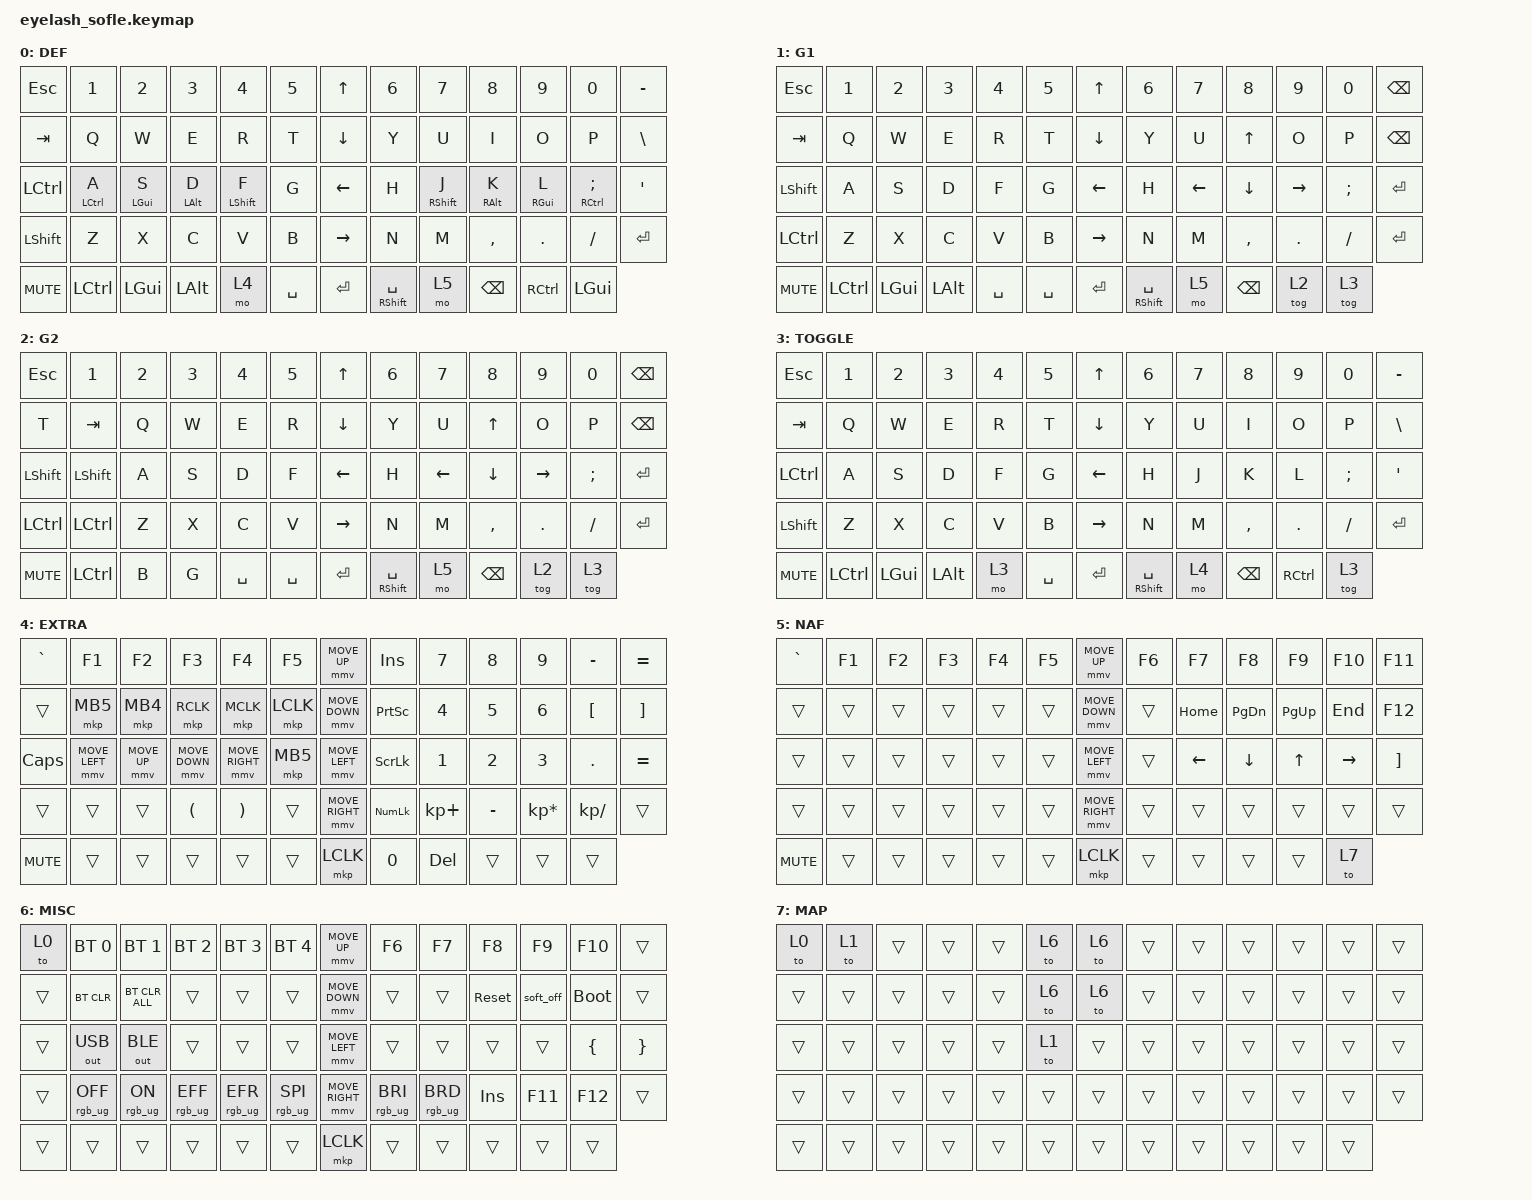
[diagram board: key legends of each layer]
#define ZMK_POINTING_DEFAULT_MOVE_VAL 1200  // 600
#define ZMK_POINTING_DEFAULT_SCRL_VAL 1   // 10

#include <input/processors.dtsi>
#include <zephyr/dt-bindings/input/input-event-codes.h>
#include <behaviors.dtsi>
#include <dt-bindings/zmk/bt.h>
#include <dt-bindings/zmk/ext_power.h>
#include <dt-bindings/zmk/keys.h>
#include <dt-bindings/zmk/pointing.h>
#include <dt-bindings/zmk/rgb.h>
#include <dt-bindings/zmk/outputs.h>

&mmv_input_listener { input-processors = <&zip_xy_scaler 2 1>; };

// &msc_input_listener { input-processors = <&zip_scroll_scaler 2 1>; };

&msc {
    acceleration-exponent = <0>;      // 0
    time-to-max-speed-ms = <300>;       // 300
    delay-ms = <0>;                   // 0
    trigger-period-ms = <2>;
};

&mmv {
    acceleration-exponent = <1>;
    time-to-max-speed-ms = <500>;
    trigger-period-ms = <16>;
};


/ {
    behaviors {
        hml: home_row_mod_left {
            compatible = "zmk,behavior-hold-tap";
            #binding-cells = <2>;
            flavor = "balanced";
            require-prior-idle-ms = <150>;
            tapping-term-ms = <280>;
            quick-tap-ms = <175>;
            bindings = <&kp>, <&kp>;

            hold-trigger-key-positions = < 8 9 10 11 12 13 21 22 23 24 25 26 34 35 36 37 38 39 46 47 48 49 50 51>; // List of keys on the right side of the keyboard
            hold-trigger-on-release;
        };

        hmr: home_row_mod_right {
            compatible = "zmk,behavior-hold-tap";
            #binding-cells = <2>;
            flavor = "balanced";
            require-prior-idle-ms = <150>;
            tapping-term-ms = <280>;
            quick-tap-ms = <175>;
            bindings = <&kp>, <&kp>;

            hold-trigger-key-positions = < 1 2 3 4 5 6 14 15 16 17 18 19 27 28 29 30 31 32 40 41 42 43 44 45>; // List of keys on the left side of the keyboard
            hold-trigger-on-release;
        };
    };
};

/ {

    scroll_encoder_vtcl: scroll_encoder_vtcl {
        compatible = "zmk,behavior-sensor-rotate";
        #sensor-binding-cells = <0>;
        bindings = <&msc MOVE_UP>, <&msc MOVE_DOWN>;
        tap-ms = <100>;
    };

    scroll_encoder_hzntl: scroll_encoder_hzntl {
        compatible = "zmk,behavior-sensor-rotate";
        #sensor-binding-cells = <0>;
        bindings = <&msc MOVE_LEFT>, <&msc MOVE_RIGHT>;
        tap-ms = <100>;
    };

    scroll_encoder_rgb: scroll_encoder_rgb {
        compatible = "zmk,behavior-sensor-rotate";
        #sensor-binding-cells = <0>;
        bindings = <&rgb_ug RGB_BRD>, <&rgb_ug RGB_BRI>;
        tap-ms = <100>;
    };

    keymap {
        compatible = "zmk,keymap";

        def_0 {
            bindings = <
&kp ESC     &kp N1          &kp N2         &kp N3          &kp N4          &kp N5          &kp UP_ARROW     &kp N6          &kp N7          &kp N8         &kp N9         &kp N0          &kp MINUS
&kp TAB     &kp Q           &kp W          &kp E           &kp R           &kp T           &kp DOWN_ARROW   &kp Y           &kp U           &kp I          &kp O          &kp P           &kp BSLH
&kp LCTRL   &hml LCTRL A    &hml LGUI S    &hml LALT D     &hml LSHIFT F   &kp G           &kp LEFT_ARROW   &kp H           &hmr RSHIFT J   &hmr RALT K    &hmr RGUI L    &hmr RCTRL SEMI &kp SQT
&kp LSHFT   &kp Z           &kp X          &kp C           &kp V           &kp B           &kp RIGHT_ARROW  &kp N           &kp M           &kp COMMA      &kp DOT        &kp FSLH        &kp ENTER
&kp C_MUTE  &kp LCTRL       &kp LGUI       &kp LALT        &mo 4           &kp SPACE       &kp ENTER        &mt RSHFT SPACE &mo 5           &kp BSPC       &kp RCTRL      &kp LGUI
            >;

            sensor-bindings = <&scroll_encoder_vtcl>;
            display-name = "DEF";
        };

        gaymink_1 {
            bindings = <
&kp ESC     &kp N1          &kp N2         &kp N3          &kp N4          &kp N5          &kp UP_ARROW     &kp N6          &kp N7          &kp N8         &kp N9         &kp N0          &kp BSPC
&kp TAB     &kp Q           &kp W          &kp E           &kp R           &kp T           &kp DOWN_ARROW   &kp Y           &kp U           &kp UP         &kp O          &kp P           &kp BSPC
&kp LSHFT   &kp A           &kp S          &kp D           &kp F           &kp G           &kp LEFT_ARROW   &kp H           &kp LEFT        &kp DOWN       &kp RIGHT      &kp SEMI        &kp ENTER
&kp LCTRL   &kp Z           &kp X          &kp C           &kp V           &kp B           &kp RIGHT_ARROW  &kp N           &kp M           &kp COMMA      &kp DOT        &kp FSLH        &kp ENTER
&kp C_MUTE  &kp LCTRL       &kp LGUI       &kp LALT        &kp SPACE       &kp SPACE       &kp ENTER        &mt RSHFT SPACE &mo 5           &kp BSPC       &tog 2      &tog 3
            >;

            sensor-bindings = <&scroll_encoder_vtcl>;
            display-name = "G1";
        };

        gaymink_2 {
            bindings = <
&kp ESC     &kp N1          &kp N2         &kp N3          &kp N4          &kp N5          &kp UP_ARROW     &kp N6          &kp N7          &kp N8         &kp N9         &kp N0          &kp BSPC
&kp T       &kp TAB         &kp Q           &kp W          &kp E           &kp R           &kp DOWN_ARROW   &kp Y           &kp U           &kp UP         &kp O          &kp P           &kp BSPC
&kp LSHFT   &kp LSHFT       &kp A           &kp S          &kp D           &kp F           &kp LEFT_ARROW   &kp H           &kp LEFT        &kp DOWN       &kp RIGHT      &kp SEMI        &kp ENTER
&kp LCTRL   &kp LCTRL       &kp Z           &kp X          &kp C           &kp V           &kp RIGHT_ARROW  &kp N           &kp M           &kp COMMA      &kp DOT        &kp FSLH        &kp ENTER
&kp C_MUTE  &kp LCTRL       &kp B           &kp G          &kp SPACE       &kp SPACE       &kp ENTER        &mt RSHFT SPACE &mo 5           &kp BSPC       &tog 2         &tog 3
            >;

            sensor-bindings = <&scroll_encoder_vtcl>;
            display-name = "G2";
        };


        def_3 {
            bindings = <
&kp ESC     &kp N1          &kp N2         &kp N3          &kp N4          &kp N5          &kp UP_ARROW     &kp N6          &kp N7          &kp N8         &kp N9         &kp N0          &kp MINUS
&kp TAB     &kp Q           &kp W          &kp E           &kp R           &kp T           &kp DOWN_ARROW   &kp Y           &kp U           &kp I          &kp O          &kp P           &kp BSLH
&kp LCTRL   &kp A           &kp S          &kp D           &kp F           &kp G           &kp LEFT_ARROW   &kp H           &kp J           &kp K          &kp L          &kp SEMI        &kp SQT
&kp LSHFT   &kp Z           &kp X          &kp C           &kp V           &kp B           &kp RIGHT_ARROW  &kp N           &kp M           &kp COMMA      &kp DOT        &kp FSLH        &kp ENTER
&kp C_MUTE  &kp LCTRL       &kp LGUI       &kp LALT        &mo 3           &kp SPACE       &kp ENTER        &mt RSHFT SPACE &mo 4           &kp BSPC       &kp RCTRL      &tog 3
            >;

            sensor-bindings = <&scroll_encoder_vtcl>;
            display-name = "TOGGLE";
        };

        extra_4 {
            bindings = <
&kp GRAVE   &kp F1          &kp F2         &kp F3          &kp F4          &kp F5          &mmv MOVE_UP     &kp INS         &kp N7          &kp N8         &kp N9         &kp MINUS       &kp EQUAL
&trans      &mkp MB5        &mkp MB4       &mkp RCLK       &mkp MCLK       &mkp LCLK       &mmv MOVE_DOWN   &kp PSCRN       &kp N4          &kp N5         &kp N6         &kp LEFT_BRACKET &kp RIGHT_BRACKET
&kp CAPS    &mmv MOVE_LEFT  &mmv MOVE_UP   &mmv MOVE_DOWN  &mmv MOVE_RIGHT &mkp MB5        &mmv MOVE_LEFT   &kp SLCK        &kp N1          &kp N2         &kp N3         &kp DOT         &kp EQUAL
&trans      &trans          &trans         &kp LPAR        &kp RPAR        &trans          &mmv MOVE_RIGHT  &kp KP_NUMLOCK  &kp KP_PLUS     &kp MINUS      &kp KP_MULTIPLY&kp KP_DIVIDE   &trans
&kp C_MUTE  &trans          &trans         &trans          &trans          &trans          &mkp LCLK        &kp N0          &kp DEL         &trans         &trans         &trans
            >;

            sensor-bindings = <&inc_dec_kp C_VOLUME_UP C_VOL_DN>;
            display-name = "EXTRA";
        };

        naf_5 {
            bindings = <
&kp GRAVE   &kp F1          &kp F2         &kp F3          &kp F4          &kp F5          &mmv MOVE_UP     &kp F6          &kp F7          &kp F8         &kp F9         &kp F10        &kp F11
&trans      &trans          &trans         &trans          &trans          &trans          &mmv MOVE_DOWN   &trans          &kp HOME        &kp PG_DN      &kp PG_UP      &kp END        &kp F12
&trans      &trans          &trans         &trans          &trans          &trans          &mmv MOVE_LEFT   &trans          &kp LEFT        &kp DOWN       &kp UP         &kp RIGHT      &kp RIGHT_BRACKET
&trans      &trans          &trans         &trans          &trans          &trans          &mmv MOVE_RIGHT  &trans          &trans          &trans         &trans         &trans         &trans
&kp C_MUTE  &trans          &trans         &trans          &trans          &trans          &mkp LCLK        &trans          &trans          &trans         &trans         &to 7
            >;

            sensor-bindings = <&scroll_encoder_hzntl>;
            display-name = "NAF";
        };

        misc_6 {
            bindings = <
&to 0       &bt BT_SEL 0    &bt BT_SEL 1   &bt BT_SEL 2    &bt BT_SEL 3    &bt BT_SEL 4    &mmv MOVE_UP     &kp F6          &kp F7          &kp F8         &kp F9         &kp F10        &trans
&trans      &bt BT_CLR      &bt BT_CLR_ALL &trans          &trans          &trans          &mmv MOVE_DOWN   &trans          &trans          &sys_reset     &soft_off      &bootloader    &trans
&trans      &out OUT_USB    &out OUT_BLE   &trans          &trans          &trans          &mmv MOVE_LEFT   &trans          &trans          &trans         &trans         &kp LBRC       &kp RBRC
&trans      &rgb_ug RGB_OFF &rgb_ug RGB_ON &rgb_ug RGB_EFF &rgb_ug RGB_EFR &rgb_ug RGB_SPI &mmv MOVE_RIGHT  &rgb_ug RGB_BRI &rgb_ug RGB_BRD &kp INSERT     &kp F11        &kp F12        &trans
&trans      &trans          &trans         &trans          &trans          &trans          &mkp LCLK        &trans          &trans          &trans         &trans         &trans
            >;

            sensor-bindings = <&scroll_encoder_rgb>;
            display-name = "MISC";
        };

        map_7 {
            bindings = <
&to 0       &to 1           &trans         &trans          &trans          &to 6          &to 6            &trans          &trans          &trans         &trans         &trans         &trans
&trans      &trans          &trans         &trans          &trans          &to 6          &to 6           &trans          &trans          &trans         &trans         &trans         &trans
&trans      &trans          &trans         &trans          &trans          &to 1           &trans           &trans          &trans          &trans         &trans         &trans         &trans
&trans      &trans          &trans         &trans          &trans          &trans          &trans           &trans          &trans          &trans         &trans         &trans         &trans
&trans      &trans          &trans         &trans          &trans          &trans          &trans           &trans          &trans          &trans         &trans         &trans
            >;

            display-name = "MAP";
        };
    };
};
